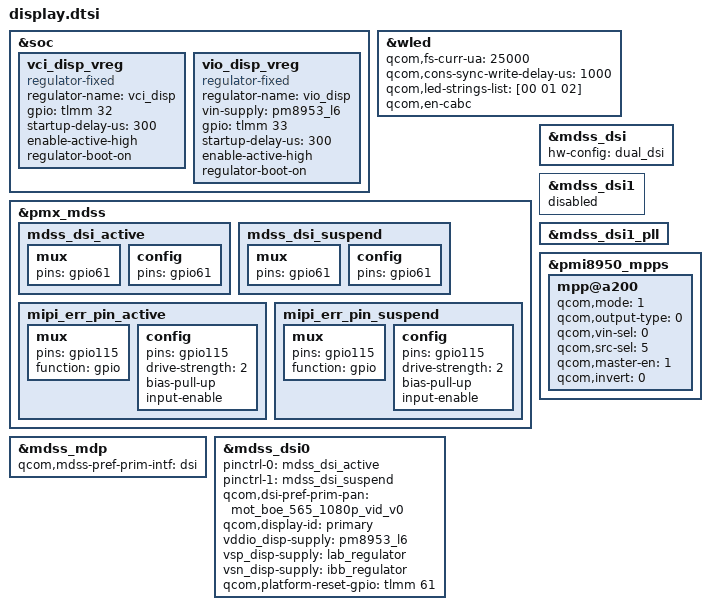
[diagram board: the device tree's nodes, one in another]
/* Copyright (c) 2018, Motorola Mobility Inc. All rights reserved.
 *
 * This program is free software; you can redistribute it and/or modify
 * it under the terms of the GNU General Public License version 2 and
 * only version 2 as published by the Free Software Foundation.
 *
 * This program is distributed in the hope that it will be useful,
 * but WITHOUT ANY WARRANTY; without even the implied warranty of
 * MERCHANTABILITY or FITNESS FOR A PARTICULAR PURPOSE.  See the
 * GNU General Public License for more details.
 */

#include "dsi-panel/dsi-panel-mot-boe-565-1080p-vid.dtsi"
#include "dsi-panel/dsi-panel-mot-tianma-565-1080p-vid.dtsi"
#include "dsi-panel/dsi-panel-mot-auo-565-1080p-vid.dtsi"

&soc {
	vci_disp_vreg: vci_disp_vreg {
		compatible = "regulator-fixed";
		regulator-name = "vci_disp";
		gpio = <&tlmm 32 0>;
		startup-delay-us = <300>;
		enable-active-high;
		regulator-boot-on;
	};

	vio_disp_vreg: vio_disp_vreg {
		compatible = "regulator-fixed";
		regulator-name = "vio_disp";
		vin-supply = <&pm8953_l6>;
		gpio = <&tlmm 33 0>;
		startup-delay-us = <300>;
		enable-active-high;
		regulator-boot-on;
	};

};

&wled {
	qcom,fs-curr-ua = <25000>;
	qcom,cons-sync-write-delay-us = <1000>;
	qcom,led-strings-list = [00 01 02];
	qcom,en-cabc;
};

&pmx_mdss {
	mdss_dsi_active {
		mux {
			pins = "gpio61";
		};

		config {
			/delete-property/ output-high;
			pins = "gpio61";
		};
	};

	mdss_dsi_suspend {
		mux {
			pins = "gpio61";
		};

		config {
			pins = "gpio61";
		};
	};

	mipi_err_pin_active: mipi_err_pin_active {
		mux {
			pins = "gpio115";
			function = "gpio";
		};

		config {
			pins = "gpio115";
			drive-strength = <2>; /* 2 mA */
			bias-pull-up; /* pull up */
			input-enable;
		};
	};

	mipi_err_pin_suspend: mipi_err_pin_suspend {
		mux {
			pins = "gpio115";
			function = "gpio";
		};

		config {
			pins = "gpio115";
			drive-strength = <2>; /* 2 mA */
			bias-pull-up; /* pull up */
			input-enable;
		};
	};
};

&mdss_mdp {
	qcom,mdss-pref-prim-intf = "dsi";
};

&mdss_dsi {
	hw-config = "dual_dsi";
};

&mdss_dsi0 {
	pinctrl-names = "mdss_default", "mdss_sleep";
	pinctrl-0 = <&mdss_dsi_active>;
	pinctrl-1 = <&mdss_dsi_suspend>;

	qcom,dsi-pref-prim-pan = <&mot_boe_565_1080p_vid_v0>;
	qcom,display-id = "primary";

	/delete-property/ vdd-supply;
	vddio_disp-supply = <&pm8953_l6>;
	vsp_disp-supply = <&lab_regulator>;
	vsn_disp-supply = <&ibb_regulator>;

	qcom,platform-reset-gpio = <&tlmm 61 0>;
};

&mdss_dsi1 {
	status = "disabled";
};

&mdss_dsi1_pll {
	/delete-property/ qcom,dsi-pll-ssc-en;
	/delete-property/ qcom,dsi-pll-ssc-mode;
};

&pmi8950_mpps {
	mpp@a200 { /* MPP 3 - DISP_AVDD_SHUTDOWN */
		qcom,mode = <1>;		/* Digital output */
		qcom,output-type = <0>;		/* CMOS logic */
		qcom,vin-sel = <0>;
		qcom,src-sel = <5>;		/* DTEST2 */
		qcom,master-en = <1>;		/* Enable GPIO */
		qcom,invert = <0>;
		status = "okay";
	};
};
